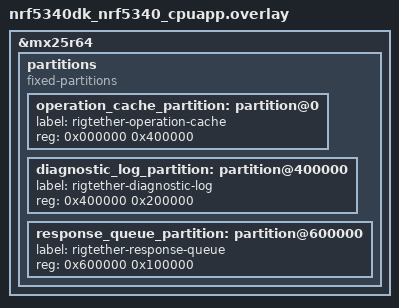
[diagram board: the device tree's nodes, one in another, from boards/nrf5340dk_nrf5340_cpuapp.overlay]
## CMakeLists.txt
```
cmake_minimum_required(VERSION 3.20.0)

find_package(Zephyr REQUIRED HINTS $ENV{ZEPHYR_BASE})
project(rigtether_m1)

target_include_directories(app PRIVATE include)
target_sources(
  app
  PRIVATE
    src/audio_service.c
    src/ble_service.c
    src/diagnostics.c
    src/main.c
    src/monotonic.c
    src/operation_cache.c
    src/protocol_service.c
    src/radio_service.c
    src/safety_service.c
    src/usb_descriptors.c
)
```

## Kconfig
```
menu "RigTether M1 fixture"

config RIGTETHER_PTT_OUTPUT_ENABLED
	bool "Enable the radio-disconnected PTT fixture output"
	default n
	help
	  Keep disabled until issue #13 defines and validates the normally-open output,
	  inhibit, downstream sense input, and pin assignment. This option must never be
	  enabled for a live-radio unattended build.

config RIGTETHER_FAULT_INJECTION
	bool "Enable labeled bench-only fault injection"
	default n
	help
	  Enables only fault inputs that release or deny PTT. It cannot assert PTT or
	  feed the watchdog.

endmenu
```

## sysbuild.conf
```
# Build the supported Bluetooth controller for the network core over HCI IPC.
SB_CONFIG_NETCORE_HCI_IPC=y
```

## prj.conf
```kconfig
# RigTether M1 nRF5340 DK application-core fixture.
CONFIG_BT=y
CONFIG_BT_PERIPHERAL=y
CONFIG_BT_DEVICE_NAME="RigTether M1"
CONFIG_BT_MAX_CONN=1
CONFIG_BT_GATT_DYNAMIC_DB=n
CONFIG_BT_GATT_SERVICE_CHANGED=n
CONFIG_BT_L2CAP_TX_MTU=517
CONFIG_BT_BUF_ACL_RX_SIZE=521
CONFIG_BT_BUF_ACL_TX_SIZE=521
CONFIG_BT_CTLR=n

CONFIG_MAIN_STACK_SIZE=4096
CONFIG_SYSTEM_WORKQUEUE_STACK_SIZE=4096
CONFIG_HEAP_MEM_POOL_SIZE=16384

CONFIG_WATCHDOG=y
CONFIG_HWINFO=y
CONFIG_NRFX_TIMER2=y
CONFIG_HW_STACK_PROTECTION=y
CONFIG_RESET_ON_FATAL_ERROR=y
CONFIG_FLASH=y
CONFIG_FLASH_MAP=y
CONFIG_NORDIC_QSPI_NOR=y

CONFIG_LOG=y
CONFIG_USE_SEGGER_RTT=y
CONFIG_LOG_BACKEND_RTT=y
CONFIG_LOG_MODE_DEFERRED=y
CONFIG_LOG_BUFFER_SIZE=8192
CONFIG_LOG_PRINTK=n
CONFIG_UART_CONSOLE=n
CONFIG_USB_CDC_ACM=n

# The canonical UAC1 descriptor is exported and validated here. Enabling the
# deprecated legacy class for physical enumeration is an explicit #18 build gate.
CONFIG_USB_DEVICE_STACK=n

# No electrical PTT pin is selected until #13 supplies the radio-disconnected
# fixture evidence. A local overlay may enable it only for that human-required work.
CONFIG_RIGTETHER_PTT_OUTPUT_ENABLED=n
CONFIG_RIGTETHER_FAULT_INJECTION=n
```

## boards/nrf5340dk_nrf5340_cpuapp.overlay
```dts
&mx25r64 {
	partitions {
		compatible = "fixed-partitions";
		#address-cells = <1>;
		#size-cells = <1>;

		operation_cache_partition: partition@0 {
			label = "rigtether-operation-cache";
			reg = <0x000000 0x400000>;
		};

		diagnostic_log_partition: partition@400000 {
			label = "rigtether-diagnostic-log";
			reg = <0x400000 0x200000>;
		};

		response_queue_partition: partition@600000 {
			label = "rigtether-response-queue";
			reg = <0x600000 0x100000>;
		};
	};
};
```

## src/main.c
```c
/* SPDX-License-Identifier: Apache-2.0 */
#include <zephyr/kernel.h>
#include <zephyr/logging/log.h>
#include <zephyr/sys/reboot.h>

#include "rigtether/audio.h"
#include "rigtether/ble_service.h"
#include "rigtether/diagnostics.h"
#include "rigtether/monotonic.h"
#include "rigtether/safety.h"

LOG_MODULE_REGISTER(rigtether, LOG_LEVEL_INF);

int main(void)
{
	int err;

	/*
	 * Initialize receive-safe ownership before transports. No BLE, CAT, USB, or
	 * response path can run before the sole PTT owner has forced inactivity.
	 */
	err = rt_monotonic_init();
	if (err != 0) {
		return err;
	}
	err = rt_audio_init();
	if (err != 0) {
		return err;
	}
	err = rt_safety_init();
	if (err != 0) {
		return err;
	}
	rt_diag_record(RT_EVENT_BOOT, 0);

	err = rt_ble_service_init();
	if (err != 0) {
		rt_safety_release(RT_RELEASE_PROTOCOL_FAULT, true);
		return err;
	}

	LOG_INF("RigTether M1 radio-disconnected fixture ready");
	LOG_WRN("PTT output and physical evidence remain disabled");
	return 0;
}
```

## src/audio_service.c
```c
/* SPDX-License-Identifier: Apache-2.0 */
#include <limits.h>
#include <zephyr/kernel.h>
#include <zephyr/sys/util.h>

#include "rigtether/audio.h"

static K_MUTEX_DEFINE(audio_lock);
static struct rt_audio_health audio_health;
static bool tx_muted = true;

int rt_audio_init(void)
{
	k_mutex_lock(&audio_lock, K_FOREVER);
	audio_health = (struct rt_audio_health){
		.configured = false,
		.tx_stream_active = false,
		.clock_healthy = false,
		.buffers_healthy = false,
		.converter_healthy = false,
	};
	tx_muted = true;
	k_mutex_unlock(&audio_lock);
	return 0;
}

void rt_audio_mute_tx(void)
{
	k_mutex_lock(&audio_lock, K_FOREVER);
	tx_muted = true;
	k_mutex_unlock(&audio_lock);
}

void rt_audio_unmute_tx(void)
{
	k_mutex_lock(&audio_lock, K_FOREVER);
	tx_muted = false;
	k_mutex_unlock(&audio_lock);
}

bool rt_audio_required_healthy(void)
{
	bool healthy;
	k_mutex_lock(&audio_lock, K_FOREVER);
	healthy = audio_health.configured && audio_health.tx_stream_active &&
		  audio_health.clock_healthy && audio_health.buffers_healthy &&
		  audio_health.converter_healthy;
	k_mutex_unlock(&audio_lock);
	return healthy;
}

void rt_audio_get_health(struct rt_audio_health *health)
{
	k_mutex_lock(&audio_lock, K_FOREVER);
	*health = audio_health;
	k_mutex_unlock(&audio_lock);
}

void rt_audio_playback_convert(const int16_t *mono, int32_t *stereo, size_t samples)
{
	for (size_t index = 0; index < samples; ++index) {
		int32_t widened = (int32_t)mono[index] * 256;
		stereo[index * 2] = widened;
		stereo[index * 2 + 1] = widened;
	}
}

void rt_audio_capture_convert(const int32_t *stereo, int16_t *mono, size_t samples)
{
	for (size_t index = 0; index < samples; ++index) {
		int32_t sample = CLAMP(stereo[index * 2], -8388608, 8388607);
		int32_t rounded =
			sample >= 0 ? (sample + 128) >> 8 : -((-sample + 128) >> 8);
		mono[index] = (int16_t)CLAMP(rounded, INT16_MIN, INT16_MAX);
	}
}
```

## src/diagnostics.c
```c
/* SPDX-License-Identifier: Apache-2.0 */
#include <zephyr/kernel.h>
#include <zephyr/sys/atomic.h>

#include "rigtether/diagnostics.h"
#include "rigtether/monotonic.h"

#define EVENT_COUNT 128

struct event_record {
	uint64_t at_us;
	uint32_t value;
	uint16_t code;
};

static struct event_record events[EVENT_COUNT];
static atomic_t write_index;
static atomic_t dropped;

void rt_diag_record(enum rt_event_code code, uint32_t value)
{
	atomic_val_t index = atomic_inc(&write_index);
	if ((uint32_t)index >= EVENT_COUNT) {
		atomic_inc(&dropped);
	}
	struct event_record *record = &events[(uint32_t)index % EVENT_COUNT];
	record->at_us = rt_monotonic_us();
	record->value = value;
	record->code = (uint16_t)code;
}

uint32_t rt_diag_dropped(void)
{
	return (uint32_t)atomic_get(&dropped);
}
```

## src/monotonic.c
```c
/* SPDX-License-Identifier: Apache-2.0 */
#include <errno.h>
#include <nrfx_timer.h>
#include <zephyr/kernel.h>
#include <zephyr/irq.h>
#include <zephyr/sys/atomic.h>

#include "rigtether/monotonic.h"

static const nrfx_timer_t lease_timer = NRFX_TIMER_INSTANCE(2);
static atomic_t timer_high;

static void timer_handler(nrf_timer_event_t event_type, void *context)
{
	ARG_UNUSED(context);
	if (event_type == NRF_TIMER_EVENT_COMPARE0) {
		atomic_inc(&timer_high);
	}
}

int rt_monotonic_init(void)
{
	nrfx_timer_config_t config =
		NRFX_TIMER_DEFAULT_CONFIG(NRF_TIMER_FREQ_1MHz);
	config.bit_width = NRF_TIMER_BIT_WIDTH_32;
	int err = nrfx_timer_init(&lease_timer, &config, timer_handler);
	if (err != NRFX_SUCCESS) {
		return -EIO;
	}
	nrfx_timer_clear(&lease_timer);
	nrfx_timer_extended_compare(&lease_timer, NRF_TIMER_CC_CHANNEL0, UINT32_MAX,
				    NRF_TIMER_SHORT_COMPARE0_CLEAR_MASK, true);
	nrfx_timer_enable(&lease_timer);
	return 0;
}

uint64_t rt_monotonic_us(void)
{
	/*
	 * Synchronize with the wrap ISR and account for a compare event that became
	 * pending before the ISR could advance the software epoch. If the event
	 * arrived after capture, low is still in the upper half and belongs to the
	 * old epoch; otherwise the cleared counter belongs to the next epoch.
	 */
	unsigned int irq_key = irq_lock();
	uint32_t high = (uint32_t)atomic_get(&timer_high);
	uint32_t low = nrfx_timer_capture(&lease_timer, NRF_TIMER_CC_CHANNEL1);
	bool wrap_pending =
		nrf_timer_event_check(lease_timer.p_reg, NRF_TIMER_EVENT_COMPARE0);
	if (wrap_pending && low < (UINT32_MAX / 2U)) {
		high++;
	}
	irq_unlock(irq_key);

	return ((uint64_t)high << 32) | low;
}
```

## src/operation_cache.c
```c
/* SPDX-License-Identifier: Apache-2.0 */
#include <errno.h>
#include <string.h>
#include <zephyr/storage/flash_map.h>
#include <zephyr/sys/crc.h>
#include <zephyr/sys/util.h>

#include "rigtether/operation_cache.h"

#define CACHE_MAGIC 0x52544330U
#define CACHE_LIMIT 512
#define RESPONSE_QUEUE_LIMIT 512
#define MAX_LOGICAL_BYTES 1024

struct cache_record_header {
	uint32_t magic;
	uint32_t crc;
	uint64_t seq;
	uint16_t request_length;
	uint16_t response_length;
	char op_id[32];
} __packed;

struct cache_index {
	uint32_t offset;
	uint64_t seq;
	uint16_t request_length;
	uint16_t response_length;
	char op_id[33];
};

struct queue_record_header {
	uint32_t magic;
	uint32_t crc;
	uint16_t response_length;
	uint16_t reserved;
} __packed;

static const struct flash_area *cache_area;
static const struct flash_area *response_queue_area;
static struct cache_index index_entries[CACHE_LIMIT];
static size_t index_count;
static uint32_t next_offset;
static uint8_t record_buffer[sizeof(struct cache_record_header) +
			     MAX_LOGICAL_BYTES * 2 + 4] __aligned(4);
static uint32_t queue_offsets[RESPONSE_QUEUE_LIMIT];
static uint16_t queue_lengths[RESPONSE_QUEUE_LIMIT];
static size_t queue_head;
static size_t queue_tail;
static size_t queue_count;
static uint32_t queue_next_offset;
static uint8_t queue_record_buffer[sizeof(struct queue_record_header) +
				   MAX_LOGICAL_BYTES + 4] __aligned(4);

static size_t aligned_record_size(size_t request_length, size_t response_length)
{
	return ROUND_UP(sizeof(struct cache_record_header) + request_length +
				response_length,
			4);
}

int rt_operation_cache_init(void)
{
	int err = flash_area_open(FIXED_PARTITION_ID(operation_cache_partition),
				  &cache_area);
	if (err != 0) {
		return err;
	}
	err = flash_area_open(FIXED_PARTITION_ID(response_queue_partition),
			      &response_queue_area);
	if (err != 0) {
		return err;
	}
	err = rt_operation_cache_reset();
	return err != 0 ? err : rt_response_queue_reset();
}

int rt_operation_cache_reset(void)
{
	if (cache_area == NULL) {
		return -ENODEV;
	}
	int err = flash_area_erase(cache_area, 0, flash_area_get_size(cache_area));
	if (err == 0) {
		index_count = 0;
		next_offset = 0;
	}
	return err;
}

int rt_operation_cache_lookup(const char *op_id, uint64_t seq,
			      const uint8_t *request, size_t request_length,
			      uint8_t *response, size_t response_capacity,
			      size_t *response_length,
			      enum rt_cache_lookup *lookup)
{
	*lookup = RT_CACHE_MISS;
	for (size_t entry_index = 0; entry_index < index_count; ++entry_index) {
		const struct cache_index *entry = &index_entries[entry_index];
		if (strcmp(entry->op_id, op_id) != 0) {
			continue;
		}
		if (entry->seq != seq || entry->request_length != request_length) {
			*lookup = RT_CACHE_ALTERED;
			return 0;
		}
		size_t record_size =
			aligned_record_size(entry->request_length, entry->response_length);
		int err = flash_area_read(cache_area, entry->offset, record_buffer,
					  record_size);
		if (err != 0) {
			return err;
		}
		struct cache_record_header *header =
			(struct cache_record_header *)record_buffer;
		if (header->magic != CACHE_MAGIC ||
		    header->crc != crc32_ieee(
					   &record_buffer[sizeof(*header)],
					   entry->request_length +
						   entry->response_length)) {
			return -EILSEQ;
		}
		const uint8_t *stored_request = &record_buffer[sizeof(*header)];
		if (memcmp(stored_request, request, request_length) != 0) {
			*lookup = RT_CACHE_ALTERED;
			return 0;
		}
		if (entry->response_length > response_capacity) {
			return -EMSGSIZE;
		}
		memcpy(response, &stored_request[entry->request_length],
		       entry->response_length);
		*response_length = entry->response_length;
		*lookup = RT_CACHE_EXACT;
		return 0;
	}
	return 0;
}

int rt_operation_cache_store(const char *op_id, uint64_t seq,
			     const uint8_t *request, size_t request_length,
			     const uint8_t *response, size_t response_length)
{
	if (index_count >= CACHE_LIMIT || request_length > MAX_LOGICAL_BYTES ||
	    response_length > MAX_LOGICAL_BYTES) {
		return -ENOSPC;
	}
	size_t record_size = aligned_record_size(request_length, response_length);
	if (next_offset + record_size > flash_area_get_size(cache_area)) {
		return -ENOSPC;
	}
	memset(record_buffer, 0xff, record_size);
	struct cache_record_header *header =
		(struct cache_record_header *)record_buffer;
	*header = (struct cache_record_header){
		.magic = CACHE_MAGIC,
		.seq = seq,
		.request_length = request_length,
		.response_length = response_length,
	};
	memcpy(header->op_id, op_id, 32);
	uint8_t *stored_request = &record_buffer[sizeof(*header)];
	memcpy(stored_request, request, request_length);
	memcpy(&stored_request[request_length], response, response_length);
	header->crc =
		crc32_ieee(stored_request, request_length + response_length);
	int err =
		flash_area_write(cache_area, next_offset, record_buffer, record_size);
	if (err != 0) {
		return err;
	}
	struct cache_index *entry = &index_entries[index_count++];
	*entry = (struct cache_index){
		.offset = next_offset,
		.seq = seq,
		.request_length = request_length,
		.response_length = response_length,
	};
	memcpy(entry->op_id, op_id, 32);
	entry->op_id[32] = '\0';
	next_offset += record_size;
	return 0;
}

size_t rt_operation_cache_count(void)
{
	return index_count;
}

int rt_response_queue_reset(void)
{
	if (response_queue_area == NULL) {
		return -ENODEV;
	}
	int err = flash_area_erase(response_queue_area, 0,
				   flash_area_get_size(response_queue_area));
	if (err == 0) {
		queue_head = 0;
		queue_tail = 0;
		queue_count = 0;
		queue_next_offset = 0;
	}
	return err;
}

int rt_response_queue_enqueue(const uint8_t *response, size_t response_length)
{
	if (response_length == 0 || response_length > MAX_LOGICAL_BYTES ||
	    queue_count >= RESPONSE_QUEUE_LIMIT) {
		return -ENOSPC;
	}
	size_t record_size =
		ROUND_UP(sizeof(struct queue_record_header) + response_length, 4);
	if (queue_next_offset + record_size >
	    flash_area_get_size(response_queue_area)) {
		if (queue_count != 0) {
			return -ENOSPC;
		}
		int err = rt_response_queue_reset();
		if (err != 0) {
			return err;
		}
	}
	memset(queue_record_buffer, 0xff, record_size);
	struct queue_record_header *header =
		(struct queue_record_header *)queue_record_buffer;
	*header = (struct queue_record_header){
		.magic = CACHE_MAGIC,
		.response_length = response_length,
	};
	uint8_t *stored_response = &queue_record_buffer[sizeof(*header)];
	memcpy(stored_response, response, response_length);
	header->crc = crc32_ieee(stored_response, response_length);
	int err = flash_area_write(response_queue_area, queue_next_offset,
				   queue_record_buffer, record_size);
	if (err != 0) {
		return err;
	}
	queue_offsets[queue_tail] = queue_next_offset;
	queue_lengths[queue_tail] = response_length;
	queue_tail = (queue_tail + 1) % RESPONSE_QUEUE_LIMIT;
	queue_count++;
	queue_next_offset += record_size;
	return 0;
}

int rt_response_queue_dequeue(uint8_t *response, size_t response_capacity,
			      size_t *response_length)
{
	if (queue_count == 0) {
		return 0;
	}
	uint16_t length = queue_lengths[queue_head];
	if (length > response_capacity) {
		return -EMSGSIZE;
	}
	size_t record_size =
		ROUND_UP(sizeof(struct queue_record_header) + length, 4);
	int err = flash_area_read(response_queue_area, queue_offsets[queue_head],
				  queue_record_buffer, record_size);
	if (err != 0) {
		return err;
	}
	struct queue_record_header *header =
		(struct queue_record_header *)queue_record_buffer;
	const uint8_t *stored_response = &queue_record_buffer[sizeof(*header)];
	if (header->magic != CACHE_MAGIC || header->response_length != length ||
	    header->crc != crc32_ieee(stored_response, length)) {
		return -EILSEQ;
	}
	memcpy(response, stored_response, length);
	*response_length = length;
	queue_head = (queue_head + 1) % RESPONSE_QUEUE_LIMIT;
	queue_count--;
	return 1;
}

size_t rt_response_queue_count(void)
{
	return queue_count;
}
```

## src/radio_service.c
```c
/* SPDX-License-Identifier: Apache-2.0 */
#include <errno.h>
#include <zephyr/sys/util.h>

#include "rigtether/radio.h"

static enum rt_radio_profile selected_profile = RT_RADIO_PROFILE_KX2;

void rt_radio_select_profile(enum rt_radio_profile profile)
{
	selected_profile = profile;
}

int rt_radio_execute_typed(const struct rt_radio_request *request,
			   struct rt_radio_outcome *outcome)
{
	ARG_UNUSED(request);
	ARG_UNUSED(selected_profile);

	/*
	 * Issue #13 has not selected or validated a radio-side CAT electrical
	 * interface. The nRF fixture therefore has no RadioIo backend and must not
	 * manufacture a successful query. The hardware-independent Rust firmware
	 * core binds this same typed operation set to the #9 transcript simulator.
	 * There is deliberately no raw-CAT entry point in this interface.
	 */
	outcome->error_code = "radio_disconnected";
	outcome->result_json = NULL;
	return -ENOTCONN;
}
```

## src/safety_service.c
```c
/* SPDX-License-Identifier: Apache-2.0 */
#include <errno.h>
#include <string.h>
#include <zephyr/device.h>
#include <zephyr/drivers/hwinfo.h>
#include <zephyr/drivers/watchdog.h>
#include <zephyr/kernel.h>
#include <zephyr/sys/util.h>

#include "rigtether/audio.h"
#include "rigtether/ble_service.h"
#include "rigtether/diagnostics.h"
#include "rigtether/monotonic.h"
#include "rigtether/safety.h"

#define SAFETY_PERIOD_MS 25
#define WATCHDOG_TIMEOUT_MS 250
#define LEASE_MAX_MS 500
#define RELEASE_MAX_MS 100
#define ASSERTION_CHECK_MS (RELEASE_MAX_MS - SAFETY_PERIOD_MS)
#define CONTINUOUS_MAX_MS 60000
#define REARM_MIN_MS 1000
#define MAX_SESSION_OPERATIONS 512

static K_MUTEX_DEFINE(safety_lock);
static struct rt_safety_snapshot state;
static const struct device *watchdog;
static int watchdog_channel = -1;
static uint32_t next_fault_id = 1;
static char expired_lease_ids[MAX_SESSION_OPERATIONS][33];
static size_t expired_lease_count;
static bool assertion_pending;
static uint64_t assertion_deadline_ms;
static bool deassertion_pending;
static uint64_t deassertion_started_ms;
static bool capped_intent_present;
static char capped_intent_id[33];

static void status_notify_work_handler(struct k_work *work)
{
	ARG_UNUSED(work);
	rt_ble_notify_status();
}

K_WORK_DEFINE(status_notify_work, status_notify_work_handler);

static void status_changed(void)
{
	(void)k_work_submit(&status_notify_work);
}

static void ptt_output_inactive(void)
{
	/*
	 * No GPIO is selected until #13. The board image therefore has no physical
	 * assertion path. A future radio-disconnected overlay must keep this function
	 * as the sole writer and preserve passive inactive bias.
	 */
	if (state.commanded_ptt && !deassertion_pending) {
		deassertion_pending = true;
		deassertion_started_ms = rt_monotonic_ms();
	}
	state.commanded_ptt = false;
	assertion_pending = false;
	assertion_deadline_ms = 0;
}

static bool ptt_output_active(void)
{
	/*
	 * This is only a logical fixture command until #13 supplies the selected
	 * output overlay. The default image cannot reach this path because the
	 * output option and physical health inputs are unavailable.
	 */
	if (!IS_ENABLED(CONFIG_RIGTETHER_PTT_OUTPUT_ENABLED)) {
		return false;
	}
	deassertion_pending = false;
	deassertion_started_ms = 0;
	state.commanded_ptt = true;
	return true;
}

static bool inputs_allow_receive_safe(void)
{
	return !state.commanded_ptt && state.inputs.ptt_out_known &&
	       !state.inputs.ptt_out_active && state.inputs.inhibit_known &&
	       state.inputs.inhibit_closed &&
	       state.inputs.host_route == RT_HEALTH_HEALTHY &&
	       state.inputs.device_audio == RT_HEALTH_HEALTHY &&
	       state.inputs.ble == RT_HEALTH_HEALTHY &&
	       state.inputs.protocol_session == RT_HEALTH_HEALTHY &&
	       state.inputs.radio_profile == RT_HEALTH_HEALTHY;
}

static void clear_intent_locked(void)
{
	state.intent_present = false;
	state.owner_boot_id[0] = '\0';
	state.owner_session_id[0] = '\0';
	state.intent_id[0] = '\0';
}

static void clear_owner_locked(void)
{
	state.owner_present = false;
	state.lease_id[0] = '\0';
	state.lease_deadline_ms = 0;
}

static void clear_expired_leases_locked(void)
{
	expired_lease_count = 0;
}

static bool lease_expired_locked(const char *lease_id)
{
	for (size_t index = 0; index < expired_lease_count; ++index) {
		if (strcmp(expired_lease_ids[index], lease_id) == 0) {
			return true;
		}
	}
	return false;
}

static void record_expired_lease_locked(const char *lease_id)
{
	if (lease_expired_locked(lease_id)) {
		return;
	}
	/*
	 * Every lease consumes at least one of the session's 512 operations, so
	 * this fixed history cannot fill before the protocol session is exhausted.
	 */
	if (expired_lease_count < ARRAY_SIZE(expired_lease_ids)) {
		strcpy(expired_lease_ids[expired_lease_count++], lease_id);
	}
}

static void refresh_rearm_locked(uint64_t now)
{
	if (state.state != RT_FAULT_LOCKOUT ||
	    state.first_fault != RT_RELEASE_CONTINUOUS_CAP ||
	    !state.cap_release_reported || !inputs_allow_receive_safe()) {
		state.rearm_started_present = false;
		state.rearm_started_ms = 0;
		return;
	}
	if (!state.rearm_started_present) {
		state.rearm_started_present = true;
		state.rearm_started_ms = now;
	}
}

static void release_locked(enum rt_release_cause cause, bool lockout)
{
	if (cause == RT_RELEASE_CONTINUOUS_CAP && state.intent_present) {
		capped_intent_present = true;
		strcpy(capped_intent_id, state.intent_id);
	}
	ptt_output_inactive();
	rt_audio_mute_tx();
	if (cause == RT_RELEASE_LEASE_EXPIRED && state.owner_present) {
		record_expired_lease_locked(state.lease_id);
	}
	clear_owner_locked();
	state.continuous_started_ms = 0;
	state.last_release = cause;
	state.last_release_at_ms = rt_monotonic_ms();
	if (!lockout && cause != RT_RELEASE_CONTINUOUS_CAP) {
		clear_intent_locked();
	}
	if (lockout) {
		state.state = RT_FAULT_LOCKOUT;
		if (!state.first_fault_present) {
			state.first_fault_present = true;
			state.first_fault_id = next_fault_id++;
			state.first_fault = cause;
			state.first_fault_at_ms = state.last_release_at_ms;
			rt_diag_record(RT_EVENT_FIRST_FAULT, cause);
		}
	} else if (state.state != RT_FAULT_LOCKOUT &&
		   inputs_allow_receive_safe()) {
		state.state = RT_RECEIVE_SAFE;
	}
	if (cause == RT_RELEASE_CONTINUOUS_CAP) {
		state.cap_release_reported = false;
		state.rearm_started_present = false;
		state.rearm_started_ms = 0;
	}
	refresh_rearm_locked(state.last_release_at_ms);
	rt_diag_record(RT_EVENT_RELEASE, cause);
}

void rt_safety_release(enum rt_release_cause cause, bool lockout)
{
	k_mutex_lock(&safety_lock, K_FOREVER);
	release_locked(cause, lockout);
	k_mutex_unlock(&safety_lock);
	status_changed();
}

void rt_safety_ble_connected(void)
{
	k_mutex_lock(&safety_lock, K_FOREVER);
	state.inputs.ble = RT_HEALTH_HEALTHY;
	/* Connection is not a session and cannot restore host-route health. */
	state.inputs.protocol_session = RT_HEALTH_UNKNOWN;
	state.inputs.host_route = RT_HEALTH_UNKNOWN;
	refresh_rearm_locked(rt_monotonic_ms());
	k_mutex_unlock(&safety_lock);
	status_changed();
}

void rt_safety_ble_disconnected(void)
{
	rt_safety_release(RT_RELEASE_BLE_DISCONNECT, false);
	k_mutex_lock(&safety_lock, K_FOREVER);
	state.inputs.ble = RT_HEALTH_UNHEALTHY;
	state.inputs.protocol_session = RT_HEALTH_UNHEALTHY;
	state.inputs.host_route = RT_HEALTH_UNKNOWN;
	clear_expired_leases_locked();
	refresh_rearm_locked(rt_monotonic_ms());
	k_mutex_unlock(&safety_lock);
	status_changed();
}

void rt_safety_session_replaced(void)
{
	rt_safety_release(RT_RELEASE_SESSION_REPLACED, false);
	k_mutex_lock(&safety_lock, K_FOREVER);
	state.inputs.protocol_session = RT_HEALTH_UNKNOWN;
	state.inputs.host_route = RT_HEALTH_UNKNOWN;
	clear_expired_leases_locked();
	refresh_rearm_locked(rt_monotonic_ms());
	k_mutex_unlock(&safety_lock);
	status_changed();
}

void rt_safety_protocol_session_active(void)
{
	k_mutex_lock(&safety_lock, K_FOREVER);
	state.inputs.protocol_session = RT_HEALTH_HEALTHY;
	refresh_rearm_locked(rt_monotonic_ms());
	k_mutex_unlock(&safety_lock);
	status_changed();
}

void rt_safety_protocol_fault(void)
{
	rt_safety_release(RT_RELEASE_PROTOCOL_FAULT, true);
	k_mutex_lock(&safety_lock, K_FOREVER);
	state.inputs.protocol_session = RT_HEALTH_UNHEALTHY;
	refresh_rearm_locked(rt_monotonic_ms());
	k_mutex_unlock(&safety_lock);
	status_changed();
}

void rt_safety_update_inputs(const struct rt_safety_inputs *inputs)
{
	bool release_audio = false;
	bool release_host_route = false;
	bool release_inhibit = false;
	bool release_profile = false;
	bool output_mismatch = false;
	uint64_t now = rt_monotonic_ms();

	k_mutex_lock(&safety_lock, K_FOREVER);
	state.inputs = *inputs;
	if (state.commanded_ptt && inputs->ptt_out_known &&
	    inputs->ptt_out_active) {
		assertion_pending = false;
		assertion_deadline_ms = 0;
	} else if (!state.commanded_ptt && inputs->ptt_out_known &&
		   !inputs->ptt_out_active) {
		deassertion_pending = false;
		deassertion_started_ms = 0;
	} else if (!state.commanded_ptt && inputs->ptt_out_known &&
		   inputs->ptt_out_active && !deassertion_pending) {
		deassertion_pending = true;
		deassertion_started_ms = now;
	}
	release_audio = state.commanded_ptt &&
			inputs->device_audio != RT_HEALTH_HEALTHY;
	release_host_route = state.commanded_ptt &&
			     inputs->host_route != RT_HEALTH_HEALTHY;
	release_inhibit = state.commanded_ptt &&
			  (!inputs->inhibit_known || !inputs->inhibit_closed);
	release_profile = state.commanded_ptt &&
			  inputs->radio_profile != RT_HEALTH_HEALTHY;
	output_mismatch = state.commanded_ptt &&
			  (!inputs->ptt_out_known ||
			   (!inputs->ptt_out_active &&
			    (!assertion_pending || now >= assertion_deadline_ms)));
	if (state.state == RT_TX_ACTIVE && inputs_allow_receive_safe()) {
		state.state = RT_RECEIVE_SAFE;
	}
	refresh_rearm_locked(now);
	k_mutex_unlock(&safety_lock);
	status_changed();

	if (release_inhibit && inputs->ptt_out_known &&
	    !inputs->ptt_out_active) {
		rt_safety_release(RT_RELEASE_INHIBIT, false);
	} else if (output_mismatch) {
		rt_safety_release(RT_RELEASE_OUTPUT_FAILED_ASSERT, true);
	} else if (release_inhibit) {
		rt_safety_release(RT_RELEASE_INHIBIT, false);
	} else if (release_host_route) {
		rt_safety_release(RT_RELEASE_HOST_ROUTE, false);
	} else if (release_audio) {
		rt_safety_release(RT_RELEASE_DEVICE_AUDIO, false);
	} else if (release_profile) {
		rt_safety_release(RT_RELEASE_PROFILE_FAULT, false);
	}
}

void rt_safety_snapshot(struct rt_safety_snapshot *snapshot)
{
	k_mutex_lock(&safety_lock, K_FOREVER);
	*snapshot = state;
	k_mutex_unlock(&safety_lock);
}

static enum rt_lease_result lease_precondition_locked(void)
{
	if (state.state == RT_FAULT_LOCKOUT) {
		return RT_LEASE_FAULT_LOCKOUT;
	}
	if (state.state != RT_RECEIVE_SAFE) {
		return RT_LEASE_PTT_OUT;
	}
	if (state.inputs.host_route != RT_HEALTH_HEALTHY) {
		return RT_LEASE_HOST_ROUTE;
	}
	if (state.inputs.device_audio != RT_HEALTH_HEALTHY) {
		return RT_LEASE_DEVICE_AUDIO;
	}
	if (state.inputs.ble != RT_HEALTH_HEALTHY ||
	    state.inputs.protocol_session != RT_HEALTH_HEALTHY) {
		return RT_LEASE_CONTROL;
	}
	if (state.inputs.radio_profile != RT_HEALTH_HEALTHY) {
		return RT_LEASE_PROFILE;
	}
	if (!state.inputs.inhibit_known || !state.inputs.inhibit_closed) {
		return RT_LEASE_INHIBIT;
	}
	if (!state.inputs.ptt_out_known || state.inputs.ptt_out_active) {
		return RT_LEASE_PTT_OUT;
	}
	return RT_LEASE_OK;
}

static enum rt_lease_result renew_precondition_locked(void)
{
	if (state.state == RT_FAULT_LOCKOUT) {
		return RT_LEASE_FAULT_LOCKOUT;
	}
	if (state.inputs.host_route != RT_HEALTH_HEALTHY) {
		return RT_LEASE_HOST_ROUTE;
	}
	if (state.inputs.device_audio != RT_HEALTH_HEALTHY) {
		return RT_LEASE_DEVICE_AUDIO;
	}
	if (state.inputs.ble != RT_HEALTH_HEALTHY ||
	    state.inputs.protocol_session != RT_HEALTH_HEALTHY) {
		return RT_LEASE_CONTROL;
	}
	if (state.inputs.radio_profile != RT_HEALTH_HEALTHY) {
		return RT_LEASE_PROFILE;
	}
	if (!state.inputs.inhibit_known || !state.inputs.inhibit_closed) {
		return RT_LEASE_INHIBIT;
	}
	if (!state.commanded_ptt || !state.inputs.ptt_out_known ||
	    !state.inputs.ptt_out_active) {
		return RT_LEASE_PTT_OUT;
	}
	return RT_LEASE_OK;
}

static bool intent_matches_locked(const char *boot_id, const char *session_id,
				  const char *intent_id)
{
	return state.intent_present &&
	       strcmp(state.owner_boot_id, boot_id) == 0 &&
	       strcmp(state.owner_session_id, session_id) == 0 &&
	       strcmp(state.intent_id, intent_id) == 0;
}

static bool owner_matches_locked(const char *boot_id, const char *session_id,
				 const char *intent_id, const char *lease_id)
{
	return state.owner_present &&
	       intent_matches_locked(boot_id, session_id, intent_id) &&
	       strcmp(state.lease_id, lease_id) == 0;
}

enum rt_intent_result rt_safety_intent_begin(const char *boot_id,
					     const char *session_id,
					     const char *intent_id)
{
	enum rt_intent_result result = RT_INTENT_OK;
	k_mutex_lock(&safety_lock, K_FOREVER);
	if (state.state == RT_FAULT_LOCKOUT) {
		result = RT_INTENT_FAULT_LOCKOUT;
	} else if (state.intent_present) {
		result = RT_INTENT_ACTIVE;
	} else {
		state.intent_present = true;
		strcpy(state.owner_boot_id, boot_id);
		strcpy(state.owner_session_id, session_id);
		strcpy(state.intent_id, intent_id);
	}
	k_mutex_unlock(&safety_lock);
	status_changed();
	return result;
}

enum rt_lease_result rt_safety_acquire(const char *boot_id,
				       const char *session_id,
				       const char *intent_id,
				       const char *lease_id,
				       uint32_t requested_ms,
				       uint64_t accepted_at_ms,
				       uint32_t *granted_ms,
				       uint64_t *deadline_ms)
{
	enum rt_lease_result result;
	k_mutex_lock(&safety_lock, K_FOREVER);
	if (!intent_matches_locked(boot_id, session_id, intent_id)) {
		result = RT_LEASE_INTENT_REQUIRED;
	} else if (state.owner_present) {
		result = RT_LEASE_ACTIVE;
	} else {
		result = lease_precondition_locked();
	}
	if (result == RT_LEASE_OK && !ptt_output_active()) {
		result = RT_LEASE_PTT_OUT;
	}
	if (result == RT_LEASE_OK) {
		state.owner_present = true;
		strcpy(state.lease_id, lease_id);
		state.continuous_started_ms = accepted_at_ms;
		state.lease_deadline_ms = accepted_at_ms + requested_ms;
		state.state = RT_TX_ACTIVE;
		assertion_pending = true;
		assertion_deadline_ms =
			rt_monotonic_ms() + ASSERTION_CHECK_MS;
		*granted_ms = requested_ms;
		*deadline_ms = state.lease_deadline_ms;
		rt_audio_unmute_tx();
	}
	k_mutex_unlock(&safety_lock);
	status_changed();
	return result;
}

enum rt_lease_result rt_safety_renew(const char *boot_id,
				     const char *session_id,
				     const char *intent_id,
				     const char *lease_id,
				     uint32_t requested_ms,
				     uint64_t accepted_at_ms,
				     uint32_t *granted_ms,
				     uint64_t *deadline_ms)
{
	enum rt_lease_result result = RT_LEASE_OK;
	uint64_t now = rt_monotonic_ms();
	k_mutex_lock(&safety_lock, K_FOREVER);
	if (lease_expired_locked(lease_id)) {
		result = RT_LEASE_EXPIRED;
	} else if (!owner_matches_locked(boot_id, session_id, intent_id, lease_id)) {
		result = RT_LEASE_NOT_FOUND;
	} else if (now >= state.lease_deadline_ms) {
		release_locked(RT_RELEASE_LEASE_EXPIRED, false);
		result = RT_LEASE_EXPIRED;
	} else if (now - state.continuous_started_ms >= CONTINUOUS_MAX_MS) {
		release_locked(RT_RELEASE_CONTINUOUS_CAP, true);
		result = RT_LEASE_CONTINUOUS_CAP;
	} else {
		result = renew_precondition_locked();
	}
	if (result == RT_LEASE_OK) {
		uint64_t cap_deadline =
			state.continuous_started_ms + CONTINUOUS_MAX_MS;
		uint64_t requested_deadline = accepted_at_ms + requested_ms;
		state.lease_deadline_ms = MIN(requested_deadline, cap_deadline);
		*granted_ms =
			(uint32_t)(state.lease_deadline_ms - accepted_at_ms);
		*deadline_ms = state.lease_deadline_ms;
	} else if (result == RT_LEASE_HOST_ROUTE) {
		release_locked(RT_RELEASE_HOST_ROUTE, false);
	} else if (result == RT_LEASE_DEVICE_AUDIO) {
		release_locked(RT_RELEASE_DEVICE_AUDIO, false);
	} else if (result == RT_LEASE_CONTROL) {
		release_locked(RT_RELEASE_PROTOCOL_FAULT, true);
	} else if (result == RT_LEASE_PROFILE) {
		release_locked(RT_RELEASE_PROFILE_FAULT, false);
	} else if (result == RT_LEASE_INHIBIT) {
		release_locked(RT_RELEASE_INHIBIT, false);
	} else if (result == RT_LEASE_PTT_OUT) {
		release_locked(RT_RELEASE_OUTPUT_FAILED_ASSERT, true);
	}
	k_mutex_unlock(&safety_lock);
	status_changed();
	return result;
}

bool rt_safety_operator_release(const char *intent_id)
{
	bool accepted;
	k_mutex_lock(&safety_lock, K_FOREVER);
	bool continuous_cap =
		state.state == RT_FAULT_LOCKOUT && state.first_fault_present &&
		state.first_fault == RT_RELEASE_CONTINUOUS_CAP;
	if (continuous_cap) {
		accepted = capped_intent_present &&
			   strcmp(capped_intent_id, intent_id) == 0;
	} else {
		accepted = !state.intent_present ||
			   strcmp(state.intent_id, intent_id) == 0;
	}
	if (accepted && continuous_cap) {
		ptt_output_inactive();
		rt_audio_mute_tx();
		clear_owner_locked();
		clear_intent_locked();
		capped_intent_present = false;
		capped_intent_id[0] = '\0';
		state.cap_release_reported = true;
		state.last_release = RT_RELEASE_OPERATOR;
		state.last_release_at_ms = rt_monotonic_ms();
		refresh_rearm_locked(state.last_release_at_ms);
	} else if (accepted) {
		release_locked(RT_RELEASE_OPERATOR, false);
	}
	k_mutex_unlock(&safety_lock);
	status_changed();
	return accepted;
}

enum rt_recovery_result rt_safety_recover(uint32_t fault_id)
{
	enum rt_recovery_result result;
	uint64_t now = rt_monotonic_ms();
	k_mutex_lock(&safety_lock, K_FOREVER);
	refresh_rearm_locked(now);
	if (state.state != RT_FAULT_LOCKOUT) {
		result = RT_RECOVERY_NOT_LOCKED;
	} else if (!state.first_fault_present || state.first_fault_id != fault_id) {
		result = RT_RECOVERY_WRONG_FAULT;
	} else if (!inputs_allow_receive_safe()) {
		result = RT_RECOVERY_INCOMPLETE;
	} else if (state.first_fault == RT_RELEASE_CONTINUOUS_CAP &&
		   (!state.cap_release_reported || !state.rearm_started_present ||
		    now - state.rearm_started_ms < REARM_MIN_MS)) {
		result = RT_RECOVERY_INCOMPLETE;
	} else {
		state.state = RT_RECEIVE_SAFE;
		state.first_fault_present = false;
		state.first_fault_id = 0;
		state.first_fault_at_ms = 0;
		clear_intent_locked();
		state.cap_release_reported = false;
		state.rearm_started_present = false;
		state.rearm_started_ms = 0;
		capped_intent_present = false;
		capped_intent_id[0] = '\0';
		result = RT_RECOVERY_OK;
	}
	k_mutex_unlock(&safety_lock);
	status_changed();
	return result;
}

bool rt_safety_complete_check_and_feed_watchdog(void)
{
	bool complete = false;
	uint64_t now = rt_monotonic_ms();

	k_mutex_lock(&safety_lock, K_FOREVER);
	if (state.commanded_ptt && state.owner_present &&
	    (now >= state.lease_deadline_ms ||
	     now - state.continuous_started_ms >= CONTINUOUS_MAX_MS)) {
		enum rt_release_cause cause =
			now - state.continuous_started_ms >= CONTINUOUS_MAX_MS ?
				RT_RELEASE_CONTINUOUS_CAP :
				RT_RELEASE_LEASE_EXPIRED;
		k_mutex_unlock(&safety_lock);
		rt_safety_release(cause, cause == RT_RELEASE_CONTINUOUS_CAP);
		k_mutex_lock(&safety_lock, K_FOREVER);
		now = rt_monotonic_ms();
	}

	if (state.commanded_ptt && assertion_pending) {
		if (state.inputs.ptt_out_known &&
		    state.inputs.ptt_out_active) {
			assertion_pending = false;
			assertion_deadline_ms = 0;
		} else if (now >= assertion_deadline_ms) {
			k_mutex_unlock(&safety_lock);
			rt_safety_release(RT_RELEASE_OUTPUT_FAILED_ASSERT, true);
			return false;
		}
	}

	if (!state.commanded_ptt && deassertion_pending &&
	    state.inputs.ptt_out_known && state.inputs.ptt_out_active &&
	    now - deassertion_started_ms >= RELEASE_MAX_MS) {
		deassertion_pending = false;
		deassertion_started_ms = 0;
		k_mutex_unlock(&safety_lock);
		rt_safety_release(RT_RELEASE_OUTPUT_STUCK_ACTIVE, true);
		return false;
	}

	complete = !state.commanded_ptt ||
		   (state.owner_present && state.lease_deadline_ms > now &&
		    state.lease_deadline_ms - now <= LEASE_MAX_MS &&
		    state.inputs.ptt_out_known &&
		    state.inputs.ptt_out_active &&
		    state.inputs.inhibit_known && state.inputs.inhibit_closed &&
		    state.inputs.host_route == RT_HEALTH_HEALTHY &&
		    state.inputs.device_audio == RT_HEALTH_HEALTHY &&
		    state.inputs.ble == RT_HEALTH_HEALTHY &&
		    state.inputs.protocol_session == RT_HEALTH_HEALTHY &&
		    state.inputs.radio_profile == RT_HEALTH_HEALTHY);
	k_mutex_unlock(&safety_lock);

	if (complete && watchdog_channel >= 0 &&
	    wdt_feed(watchdog, watchdog_channel) == 0) {
		rt_diag_record(RT_EVENT_WATCHDOG_FEED, 0);
		return true;
	}
	return false;
}

static void safety_thread(void)
{
	while (true) {
		(void)rt_safety_complete_check_and_feed_watchdog();
		k_sleep(K_MSEC(SAFETY_PERIOD_MS));
	}
}

K_THREAD_DEFINE(safety_thread_id, 2048, safety_thread, NULL, NULL, NULL, -2, 0,
		K_FOREVER);

int rt_safety_init(void)
{
	uint32_t reset_cause = 0;
	enum rt_release_cause initial_release = RT_RELEASE_BOOT_OR_UPDATE;
	if (hwinfo_get_reset_cause(&reset_cause) == 0) {
		if ((reset_cause & RESET_WATCHDOG) != 0U) {
			initial_release = RT_RELEASE_WATCHDOG;
		}
		(void)hwinfo_clear_reset_cause();
	}
	state = (struct rt_safety_snapshot){
		.state = RT_RECEIVE_SAFE,
		.inputs = {
			.host_route = RT_HEALTH_UNKNOWN,
			.device_audio = RT_HEALTH_UNHEALTHY,
			.ble = RT_HEALTH_UNHEALTHY,
			.protocol_session = RT_HEALTH_UNHEALTHY,
			.radio_profile = RT_HEALTH_UNHEALTHY,
			.inhibit_known = false,
			.inhibit_closed = false,
			.ptt_out_known = false,
			.ptt_out_active = false,
		},
		.commanded_ptt = false,
		.last_release = initial_release,
		.last_release_at_ms = 0,
	};
	expired_lease_count = 0;
	deassertion_pending = false;
	deassertion_started_ms = 0;
	capped_intent_present = false;
	capped_intent_id[0] = '\0';
	ptt_output_inactive();
	rt_audio_mute_tx();

	watchdog = DEVICE_DT_GET(DT_NODELABEL(wdt0));
	if (!device_is_ready(watchdog)) {
		return -ENODEV;
	}
	const struct wdt_timeout_cfg config = {
		.window = {.min = 0, .max = WATCHDOG_TIMEOUT_MS},
		.flags = WDT_FLAG_RESET_SOC,
	};
	watchdog_channel = wdt_install_timeout(watchdog, &config);
	if (watchdog_channel < 0) {
		return watchdog_channel;
	}
	/* Passing zero keeps the watchdog running in sleep and debug halt. */
	int err = wdt_setup(watchdog, 0);
	if (err == 0) {
		k_thread_start(safety_thread_id);
	}
	return err;
}
```

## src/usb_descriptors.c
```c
/* SPDX-License-Identifier: Apache-2.0 */
#include <stdint.h>
#include <zephyr/sys/util.h>

#include "rigtether/audio.h"

const uint8_t rt_uac1_configuration_descriptor[192] = {
	0x09, 0x02, 0xC0, 0x00, 0x03, 0x01, 0x00, 0x80, 0xFA,
	0x09, 0x04, 0x00, 0x00, 0x00, 0x01, 0x01, 0x00, 0x00,
	0x0A, 0x24, 0x01, 0x00, 0x01, 0x46, 0x00, 0x02, 0x01, 0x02,
	0x0C, 0x24, 0x02, 0x01, 0x01, 0x01, 0x00, 0x01, 0x00, 0x00, 0x00, 0x00,
	0x09, 0x24, 0x06, 0x02, 0x01, 0x01, 0x01, 0x00, 0x00,
	0x09, 0x24, 0x03, 0x03, 0x03, 0x06, 0x00, 0x02, 0x00,
	0x0C, 0x24, 0x02, 0x04, 0x03, 0x06, 0x00, 0x01, 0x00, 0x00, 0x00, 0x00,
	0x09, 0x24, 0x06, 0x05, 0x04, 0x01, 0x01, 0x00, 0x00,
	0x09, 0x24, 0x03, 0x06, 0x01, 0x01, 0x00, 0x05, 0x00,
	0x09, 0x04, 0x01, 0x00, 0x00, 0x01, 0x02, 0x00, 0x00,
	0x09, 0x04, 0x01, 0x01, 0x01, 0x01, 0x02, 0x00, 0x00,
	0x07, 0x24, 0x01, 0x01, 0x08, 0x01, 0x00,
	0x0B, 0x24, 0x02, 0x01, 0x01, 0x02, 0x10, 0x01, 0x80, 0xBB, 0x00,
	0x09, 0x05, 0x08, 0x0D, 0x60, 0x00, 0x01, 0x00, 0x00,
	0x07, 0x25, 0x01, 0x00, 0x00, 0x00, 0x00,
	0x09, 0x04, 0x02, 0x00, 0x00, 0x01, 0x02, 0x00, 0x00,
	0x09, 0x04, 0x02, 0x01, 0x01, 0x01, 0x02, 0x00, 0x00,
	0x07, 0x24, 0x01, 0x06, 0x08, 0x01, 0x00,
	0x0B, 0x24, 0x02, 0x01, 0x01, 0x02, 0x10, 0x01, 0x80, 0xBB, 0x00,
	0x09, 0x05, 0x88, 0x0D, 0x60, 0x00, 0x01, 0x00, 0x00,
	0x07, 0x25, 0x01, 0x00, 0x00, 0x00, 0x00,
};

BUILD_ASSERT(sizeof(rt_uac1_configuration_descriptor) == 192);
```
